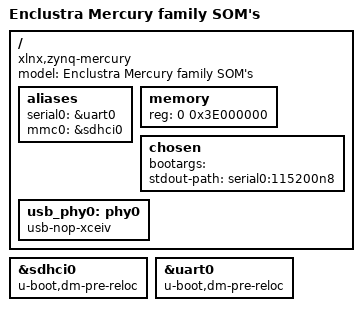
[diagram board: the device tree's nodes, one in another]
/*
 * Enclustra Mars ZX SOM devicetree
 *
 * Copyright (C) 2015 Antmicro Ltd
 *
 * SPDX-License-Identifier:	GPL-2.0+
 */
/dts-v1/;
#include "zynq-7000.dtsi"

/ {
	model = "Enclustra Mercury family SOM's";
	compatible = "xlnx,zynq-mercury","xlnx,zynq-7000";

	aliases {
		serial0 = &uart0;
        mmc0 = &sdhci0;
	};

	memory {
		device_type = "memory";
		reg = <0 0x3E000000>;
	};

	chosen {
		bootargs = "";
		stdout-path = "serial0:115200n8";
	};

	usb_phy0: phy0 {
		compatible = "usb-nop-xceiv";
		#phy-cells = <0>;
	};

};

&sdhci0 {
	u-boot,dm-pre-reloc;
	status = "okay";
};

&uart0 {
	u-boot,dm-pre-reloc;
	status = "okay";
};
